# ATxmega256A3BU device description
Architecture: AVR8_XMEGA; Family: AVR XMEGA
Registers are 8-bit, access not given, no defined reset value unless marked. A register's access mark holds for its fields unless they carry their own. Offsets are from the block's base; [hi:lo] are bit positions; lines under a group give offsets from that group; {n}, {i} and the like mark numbered series; 'fields as' and 'values as' point back to an identical list.

## USB — Universal Serial Bus
Instances: USB 0x4C0
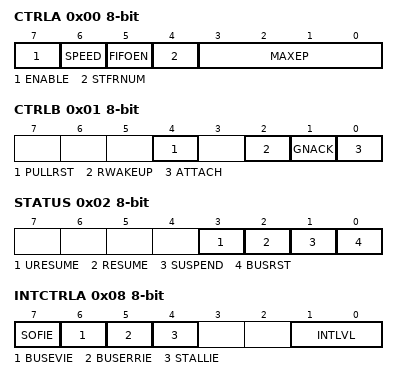
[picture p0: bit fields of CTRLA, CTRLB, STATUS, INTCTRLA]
0x00 CTRLA — Control Register A
  [7] ENABLE — USB Enable
  [6] SPEED — Speed Select
  [5] FIFOEN — USB FIFO Enable
  [4] STFRNUM — Store Frame Number Enable
  [3:0] MAXEP — Maximum Endpoint Addresses
0x01 CTRLB — Control Register B
  [4] PULLRST — Pull during Reset
  [2] RWAKEUP — Remote Wake-up
  [1] GNACK — Global NACK
  [0] ATTACH
0x02 STATUS
  [3] URESUME — Upstream Resume
  [2] RESUME
  [1] SUSPEND — Bus Suspended
  [0] BUSRST — Bus Reset
0x03 ADDR — Address Register
  [6:0] ADDR — Device Address
0x04 FIFOWP — FIFO Write Pointer Register
  [4:0] FIFOWP — FIFO Write Pointer
0x05 FIFORP — FIFO Read Pointer Register
  [4:0] FIFORP — FIFO Read Pointer
0x06 EPPTR 16-bit — Endpoint Configuration Table Pointer
0x08 INTCTRLA — Interrupt Control Register A
  [7] SOFIE — Start Of Frame Interrupt Enable
  [6] BUSEVIE — Bus Event Interrupt Enable
  [5] BUSERRIE — Bus Error Interrupt Enable
  [4] STALLIE — STALL Interrupt Enable
  [1:0] INTLVL — Interrupt Level
    0=OFF (Interrupt disabled); 1=LO (Low level); 2=MED (Medium level); 3=HI (High level)
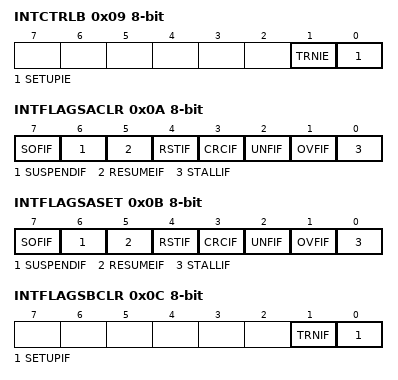
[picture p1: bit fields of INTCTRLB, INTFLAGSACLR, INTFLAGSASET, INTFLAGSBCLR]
0x09 INTCTRLB — Interrupt Control Register B
  [1] TRNIE — Transaction Complete Interrupt Enable
  [0] SETUPIE — SETUP Transaction Complete Interrupt Enable
0x0A INTFLAGSACLR — Clear Interrupt Flag Register A
  [7] SOFIF — Start Of Frame Interrupt Flag
  [6] SUSPENDIF — Suspend Interrupt Flag
  [5] RESUMEIF — Resume Interrupt Flag
  [4] RSTIF — Reset Interrupt Flag
  [3] CRCIF — Isochronous CRC Error Interrupt Flag
  [2] UNFIF — Underflow Interrupt Flag
  [1] OVFIF — Overflow Interrupt Flag
  [0] STALLIF — STALL Interrupt Flag
0x0B INTFLAGSASET — Set Interrupt Flag Register A
  fields as INTFLAGSACLR
0x0C INTFLAGSBCLR — Clear Interrupt Flag Register B
  [1] TRNIF — Transaction Complete Interrupt Flag
  [0] SETUPIF — SETUP Transaction Complete Interrupt Flag
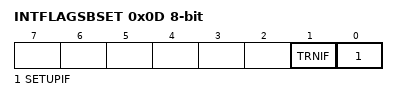
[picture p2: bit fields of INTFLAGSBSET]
0x0D INTFLAGSBSET — Set Interrupt Flag Register B
  fields as INTFLAGSBCLR
0x3A CAL0 — Calibration Byte 0
0x3B CAL1 — Calibration Byte 1

## USB_EP_TABLE — USB Endpoint Table
{0x0+0x10*i} EP{i}OUT group (i=0..15) — Endpoint {i}
  0x00 STATUS — Endpoint Status
    [7] STALLF — Endpoint Stall Flag
    [7] CRC — CRC Error Flag
    [6] UNF — Underflow Enpoint FLag
    [6] OVF — Overflow Enpoint Flag for Output Endpoints
    [5] TRNCOMPL0 — Transaction Complete 0 Flag
    [4] TRNCOMPL1 — Transaction Complete 1 Flag
    [4] SETUP — SETUP Transaction Complete Flag
    [3] BANK — Bank Select
    [2] BUSNACK1 — Data Buffer 1 Not Acknowledge
    [1] BUSNACK0 — Data Buffer 0 Not Acknowledge
    [0] TOGGLE — Data Toggle
  0x01 CTRL — Endpoint Control
    [7:6] TYPE — Endpoint Type
      0=DISABLE (Endpoint Disabled); 1=CONTROL; 2=BULK (Bulk/Interrupt); 3=ISOCHRONOUS
    [5] MULTIPKT — Multi Packet Transfer Enable
    [4] PINGPONG — Ping-Pong Enable
    [3] INTDSBL — Interrupt Disable
    [2] STALL — Data Stall
    [2:0] BUFSIZE — Data Buffer Size
      0=8 bytes buffer size; 1=16 bytes buffer size; 2=32 bytes buffer size; 3=64 bytes buffer size; 4=128 bytes buffer size; 5=256 bytes buffer size; 6=512 bytes buffer size; 7=1023 bytes buffer size
  0x02 CNT 16-bit — USB Endpoint Counter
    [15] ZLP — Zero Length Packet
  0x04 DATAPTR 16-bit — Data Pointer
  0x06 AUXDATA 16-bit — Auxiliary Data
{0x8+0x10*i} EP{i}IN group (i=0..15) — Endpoint {i}
  0x00 STATUS — Endpoint Status
    fields as EP0OUT.STATUS
  0x01 CTRL — Endpoint Control
    fields as EP0OUT.CTRL
  0x02 CNT 16-bit — USB Endpoint Counter
    [15] ZLP — Zero Length Packet
  0x04 DATAPTR 16-bit — Data Pointer
  0x06 AUXDATA 16-bit — Auxiliary Data
0x110 FRAMENUML — Frame Number Low Byte
0x111 FRAMENUMH — Frame Number High Byte
